# G32F031 register map
File version: 1.0
CPU: CM0PLUS r0p1, little endian, no MPU, no FPU, 2 interrupt priority bits
Registers are 32-bit, read-write, reset 0x0 unless marked. A register's access mark holds for its fields unless they carry their own. Offsets are from the block's base; [hi:lo] are bit positions.

## I2C — Inter-Integrated Circuit
Base 0x40004400
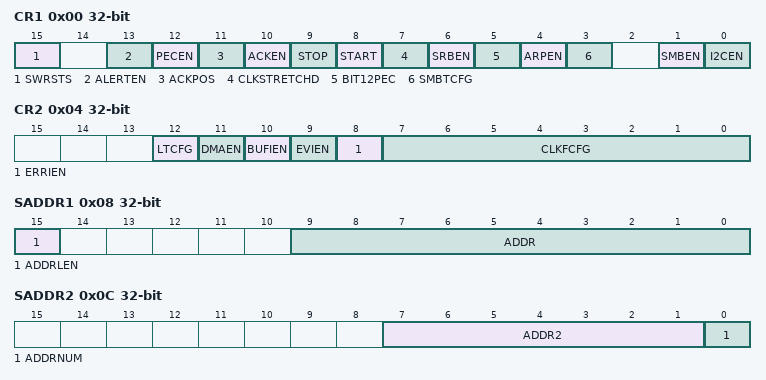
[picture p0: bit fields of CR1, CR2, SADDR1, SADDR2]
0x00 CR1 — control register 1
  [15] SWRSTS — Software Configure I2C under Reset State
  [13] ALERTEN — SMBus Alert Enable
  [12] PECEN — Packet Error Check Transfer Enable
  [11] ACKPOS — Acknowledge /PEC Position Configure
  [10] ACKEN — Acknowledge Transfer Enable
  [9] STOP — Stop Bit Transfer
  [8] START — Start Bit Transfer
  [7] CLKSTRETCHD — Slave Mode Clock Stretching Disable
  [6] SRBEN — Slave Responds Broadcast Enable
  [5] BIT12PEC — PEC Enable
  [4] ARPEN — ARP Enable
  [3] SMBTCFG — SMBus Type Configure
  [1] SMBEN — SMBus Mode Enable
  [0] I2CEN — I2C Enable
0x04 CR2 — control register 2
  [12] LTCFG — DMA Last Transfer Configure
  [11] DMAEN — DMA Requests Enable
  [10] BUFIEN — Error interrupt enable
  [9] EVIEN — Event Interrupt Enable
  [8] ERRIEN — Error Interrupt Enable
  [7:0] CLKFCFG — I2C Clock Frequency Configure
0x08 SADDR1 — Slave Mode Address Register 1
  [15] ADDRLEN — Slave Address Length Configure
  [9:0] ADDR — Slave Address Setup
0x0C SADDR2 — Slave Mode Address Register 2
  [7:1] ADDR2 — Slave Dual Address Mode Address Setup
  [0] ADDRNUM — Slave Address Number Configure
0x10 DR — data register
  [7:0] DATA
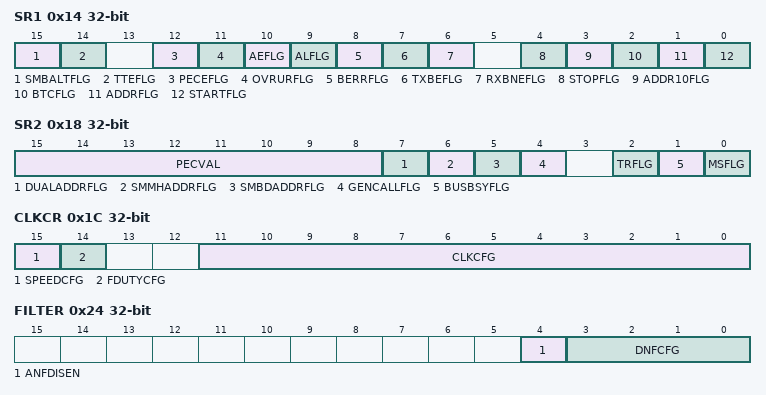
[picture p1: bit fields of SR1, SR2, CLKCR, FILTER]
0x14 SR1 access per field — Status register 1
  [15] SMBALTFLG rw — SMBus Alert Occur Flag
  [14] TTEFLG rw — Timeout or Tlow Error Flag
  [12] PECEFLG rw — PEC Error in Reception Flag
  [11] OVRURFLG rw — Overrun/Underrun Flag
  [10] AEFLG rw — Acknowledge Error Flag
  [9] ALFLG rw — Master Mode Arbitration Lost Flag
  [8] BERRFLG rw — Bus Error Flag
  [7] TXBEFLG ro — Transmit Buffer Empty Flag
  [6] RXBNEFLG ro — Receive Buffer Not Empty Flag
  [4] STOPFLG ro — Stop Bit Detection Flag
  [3] ADDR10FLG ro — 10-Bit Address Header Transmit Flag
  [2] BTCFLG ro — Byte Transfer Complete Flag
  [1] ADDRFLG ro — Address Transfer Complete / Receive Match Flag
  [0] STARTFLG ro — Start Bit Sent Finished Flag
0x18 SR2 ro — Status register 2
  [15:8] PECVAL — Save Packet Error Checking Value
  [7] DUALADDRFLG — Slave Mode Received Dual Address Match Flag
  [6] SMMHADDRFLG — SMBus Device Received Master Header Flag in Slave Mode
  [5] SMBDADDRFLG — SMBus Device Received Default Address Flag in Slave Mode
  [4] GENCALLFLG — Slave Mode Received General Call Address Flag
  [2] TRFLG — Transmitter / Receiver Mode Flag
  [1] BUSBSYFLG — Bus Busy Flag
  [0] MSFLG — Master Slave Mode Flag
0x1C CLKCR — Host Clock Control Register
  [15] SPEEDCFG — Master Mode Speed Configure
  [14] FDUTYCFG — Fast Mode Duty Cycle Configure
  [11:0] CLKCFG — Clock Setup in Fast/Standard Master Mode
0x20 RISETMAX reset 0x2 — Maximum Rise Time Register
  [7:0] RISETMAX — Master Mode Maximum Rise Time in Fast/Standard Mode
0x24 FILTER — Filter Control Register
  [4] ANFDISEN — Analog Noise Filter Disable
  [3:0] DNFCFG — Digital Noise Filter Filtering Capability Configure

## COMP0 — Comparator
Base 0x40005C00
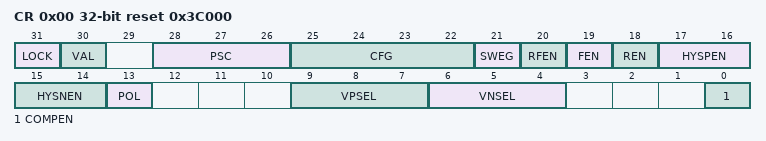
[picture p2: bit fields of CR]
0x00 CR access per field reset 0x3C000 — Control Register
  [31] LOCK rw
  [30] VAL ro — Comparator outputs the level value before polarity selector and shielding.
  [28:26] PSC rw — Digital filter fractional division configuration
  [25:22] CFG rw — Digital filter fractional clock configuration
  [21] SWEG rw — soft interrupt
  [20] RFEN rw — Comparator interrupt rising and falling edge enable
  [19] FEN rw — Comparator interrupt falling edge enable
  [18] REN rw — Comparator interrupt rising edge enable
  [17:16] HYSPEN rw — Delay function enabled
  [15:14] HYSNEN rw — Delay function enabled
  [13] POL rw — The output polarity of comparator .
  [9:7] VPSEL rw — Comparator positive input voltage selection
  [6:4] VNSEL rw — Comparator negative input voltage selection
  [0] COMPEN rw — Module enablement
0x04 ISR — Status register
  [0] IFLG — interrupt flag
